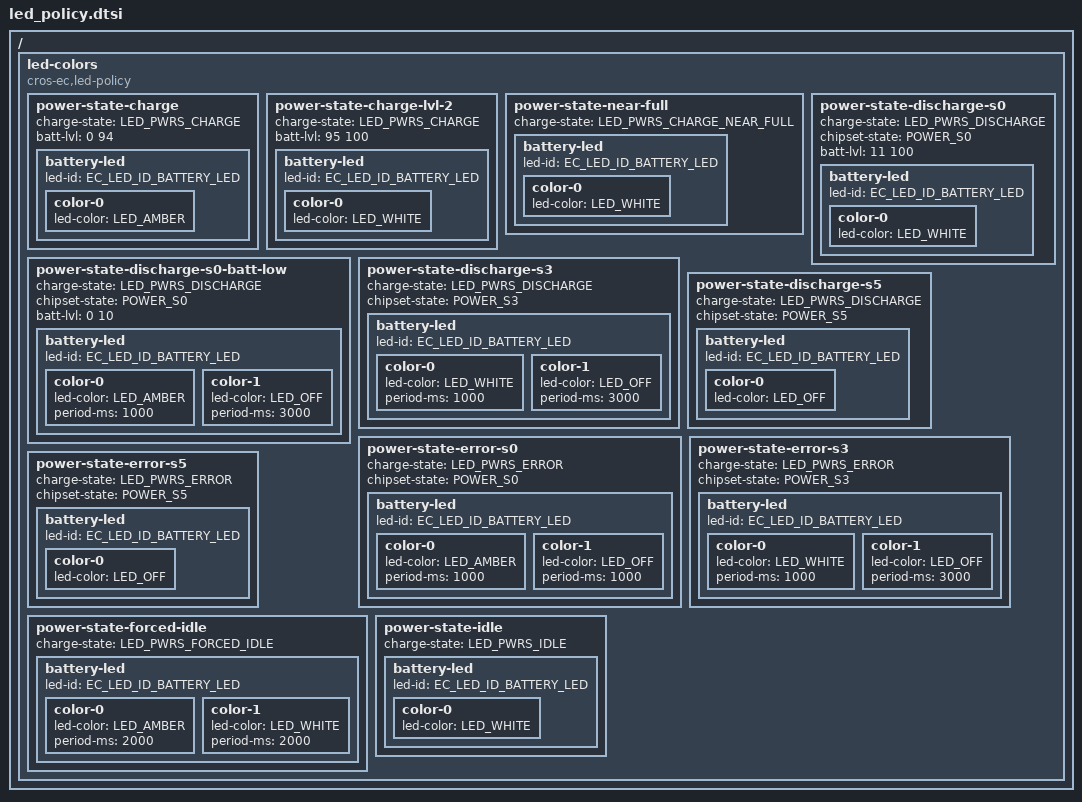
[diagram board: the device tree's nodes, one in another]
/ {
	led-colors {
		compatible = "cros-ec,led-policy";

		power-state-charge {
			charge-state = "LED_PWRS_CHARGE";
			/* Battery percent range (>= Empty, <= 94%) */
			batt-lvl = <0 94>;

			battery-led {
				led-id = "EC_LED_ID_BATTERY_LED";

				color-0 {
					led-color = "LED_AMBER";
				};
			};
		};

		power-state-charge-lvl-2 {
			charge-state = "LED_PWRS_CHARGE";
			/* Battery percent range (>= 95%, <= 100%) */
			batt-lvl = <95 100>;

			battery-led {
				led-id = "EC_LED_ID_BATTERY_LED";

				color-0 {
					led-color = "LED_WHITE";
				};
			};
		};

		power-state-near-full {
			charge-state = "LED_PWRS_CHARGE_NEAR_FULL";

			battery-led {
				led-id = "EC_LED_ID_BATTERY_LED";

				color-0 {
					led-color = "LED_WHITE";
				};
			};
		};

		power-state-discharge-s0 {
			charge-state = "LED_PWRS_DISCHARGE";
			chipset-state = "POWER_S0";
			/* Battery percent range (>= 11%, <= Full) */
			batt-lvl = <11 100>;

			battery-led {
				led-id = "EC_LED_ID_BATTERY_LED";

				color-0 {
					led-color = "LED_WHITE";
				};
			};
		};

		power-state-discharge-s0-batt-low {
			charge-state = "LED_PWRS_DISCHARGE";
			chipset-state = "POWER_S0";
			/* Battery percent range (>= Empty, <= 10%) */
			batt-lvl = <0 10>;

			battery-led {
				led-id = "EC_LED_ID_BATTERY_LED";

				/* Amber 1 sec, off 3 sec */
				color-0 {
					led-color = "LED_AMBER";
					period-ms = <1000>;
				};
				color-1 {
					led-color = "LED_OFF";
					period-ms = <3000>;
				};
			};
		};

		power-state-discharge-s3 {
			charge-state = "LED_PWRS_DISCHARGE";
			chipset-state = "POWER_S3";

			battery-led {
				led-id = "EC_LED_ID_BATTERY_LED";

				/* White 1 sec, off 3 sec */
				color-0 {
					led-color = "LED_WHITE";
					period-ms = <1000>;
				};
				color-1 {
					led-color = "LED_OFF";
					period-ms = <3000>;
				};
			};
		};

		power-state-discharge-s5 {
			charge-state = "LED_PWRS_DISCHARGE";
			chipset-state = "POWER_S5";

			battery-led {
				led-id = "EC_LED_ID_BATTERY_LED";

				color-0 {
					led-color = "LED_OFF";
				};
			};
		};

		power-state-error-s0 {
			charge-state = "LED_PWRS_ERROR";
			chipset-state = "POWER_S0";

			battery-led {
				led-id = "EC_LED_ID_BATTERY_LED";

				/* Amber 1 sec, off 1 sec */
				color-0 {
					led-color = "LED_AMBER";
					period-ms = <1000>;
				};
				color-1 {
					led-color = "LED_OFF";
					period-ms = <1000>;
				};
			};
		};

		power-state-error-s3 {
			charge-state = "LED_PWRS_ERROR";
			chipset-state = "POWER_S3";

			battery-led {
				led-id = "EC_LED_ID_BATTERY_LED";

				/* White 1 sec, off 3 sec */
				color-0 {
					led-color = "LED_WHITE";
					period-ms = <1000>;
				};
				color-1 {
					led-color = "LED_OFF";
					period-ms = <3000>;
				};
			};
		};

		power-state-error-s5 {
			charge-state = "LED_PWRS_ERROR";
			chipset-state = "POWER_S5";

			battery-led {
				led-id = "EC_LED_ID_BATTERY_LED";

				color-0 {
					led-color = "LED_OFF";
				};
			};
		};

		power-state-forced-idle {
			charge-state = "LED_PWRS_FORCED_IDLE";

			battery-led {
				led-id = "EC_LED_ID_BATTERY_LED";

				/* Amber 2 sec, White 2 sec */
				color-0 {
					led-color = "LED_AMBER";
					period-ms = <2000>;
				};
				color-1 {
					led-color = "LED_WHITE";
					period-ms = <2000>;
				};
			};
		};

		power-state-idle {
			charge-state = "LED_PWRS_IDLE";

			battery-led {
				led-id = "EC_LED_ID_BATTERY_LED";

				color-0 {
					led-color = "LED_WHITE";
				};
			};
		};
	};
};
